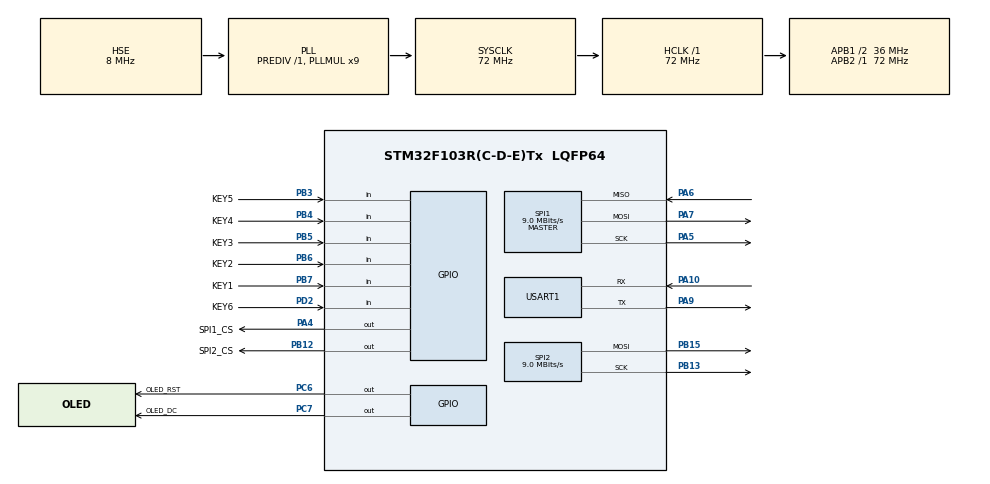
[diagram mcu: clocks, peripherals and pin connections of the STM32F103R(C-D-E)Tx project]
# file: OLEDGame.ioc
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Mcu.Family=STM32F1
Mcu.Name=STM32F103R(C-D-E)Tx
Mcu.Package=LQFP64
NVIC.PriorityGroup=NVIC_PRIORITYGROUP_4
NVIC.USART1_IRQn=true\:0\:0\:false\:false\:true\:true\:true
PA10.Mode=Asynchronous
PA10.Signal=USART1_RX
PA13.Mode=Serial_Wire
PA13.Signal=SYS_JTMS-SWDIO
PA14.Mode=Serial_Wire
PA14.Signal=SYS_JTCK-SWCLK
PA4.GPIO_Label=SPI1_CS
PA4.GPIO_Speed=GPIO_SPEED_FREQ_MEDIUM
PA4.PinState=GPIO_PIN_SET
PA4.Signal=GPIO_Output
PA5.Mode=Full_Duplex_Master
PA5.Signal=SPI1_SCK
PA6.Mode=Full_Duplex_Master
PA6.Signal=SPI1_MISO
PA7.Mode=Full_Duplex_Master
PA7.Signal=SPI1_MOSI
PA9.Mode=Asynchronous
PA9.Signal=USART1_TX
PB12.GPIO_Label=SPI2_CS
PB12.GPIO_Speed=GPIO_SPEED_FREQ_MEDIUM
PB12.PinState=GPIO_PIN_SET
PB12.Signal=GPIO_Output
PB13.Mode=TX_Only_Simplex_Unidirect_Master
PB13.Signal=SPI2_SCK
PB15.Mode=TX_Only_Simplex_Unidirect_Master
PB15.Signal=SPI2_MOSI
PB3.GPIO_Label=KEY5
PB3.GPIO_PuPd=GPIO_PULLUP
PB3.Signal=GPIO_Input
PB4.GPIO_Label=KEY4
PB4.GPIO_PuPd=GPIO_PULLUP
PB4.Signal=GPIO_Input
PB5.GPIO_Label=KEY3
PB5.GPIO_PuPd=GPIO_PULLUP
PB5.Signal=GPIO_Input
PB6.GPIO_Label=KEY2
PB6.GPIO_PuPd=GPIO_PULLUP
PB6.Signal=GPIO_Input
PB7.GPIO_Label=KEY1
PB7.GPIO_PuPd=GPIO_PULLUP
PB7.Signal=GPIO_Input
PC6.GPIO_Label=OLED_RST
PC6.GPIO_Speed=GPIO_SPEED_FREQ_MEDIUM
PC6.PinState=GPIO_PIN_SET
PC6.Signal=GPIO_Output
PC7.GPIO_Label=OLED_DC
PC7.GPIO_Speed=GPIO_SPEED_FREQ_MEDIUM
PC7.PinState=GPIO_PIN_SET
PC7.Signal=GPIO_Output
PD0-OSC_IN.Mode=HSE-External-Oscillator
PD0-OSC_IN.Signal=RCC_OSC_IN
PD1-OSC_OUT.Mode=HSE-External-Oscillator
PD1-OSC_OUT.Signal=RCC_OSC_OUT
PD2.GPIO_Label=KEY6
PD2.GPIO_PuPd=GPIO_PULLUP
PD2.Signal=GPIO_Input
ProjectManager.HeapSize=0x200
ProjectManager.StackSize=0x400
ProjectManager.TargetToolchain=MDK-ARM V5
RCC.AHBFreq_Value=72000000
RCC.APB1CLKDivider=RCC_HCLK_DIV2
RCC.APB1Freq_Value=36000000
RCC.APB1TimFreq_Value=72000000
RCC.APB2Freq_Value=72000000
RCC.APB2TimFreq_Value=72000000
RCC.EnbaleCSS=true
RCC.HCLKFreq_Value=72000000
RCC.PLLMUL=RCC_PLL_MUL9
RCC.PLLSourceVirtual=RCC_PLLSOURCE_HSE
RCC.SYSCLKFreq_VALUE=72000000
RCC.SYSCLKSource=RCC_SYSCLKSOURCE_PLLCLK
RCC.USBFreq_Value=72000000
SPI1.BaudRatePrescaler=SPI_BAUDRATEPRESCALER_8
SPI1.CalculateBaudRate=9.0 MBits/s
SPI1.Direction=SPI_DIRECTION_2LINES
SPI1.Mode=SPI_MODE_MASTER
SPI1.VirtualType=VM_MASTER
SPI2.BaudRatePrescaler=SPI_BAUDRATEPRESCALER_4
SPI2.CalculateBaudRate=9.0 MBits/s
SPI2.Direction=SPI_DIRECTION_2LINES
SPI2.Mode=SPI_MODE_MASTER
SPI2.VirtualType=VM_MASTER
USART1.VirtualMode=VM_ASYNC
board=custom

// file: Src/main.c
/* USER CODE BEGIN Header */
/**
  ******************************************************************************
  * @file           : main.c
  * @brief          : Main program body
  ******************************************************************************
  * @attention
  *
  * <h2><center>&copy; Copyright (c) 2020 STMicroelectronics.
  * All rights reserved.</center></h2>
  *
  * This software component is licensed by ST under BSD 3-Clause license,
  * the "License"; You may not use this file except in compliance with the
  * License. You may obtain a copy of the License at:
  *                        opensource.org/licenses/BSD-3-Clause
  *
  ******************************************************************************
  */
/* USER CODE END Header */

#include "main.h"
#include "spi.h"
#include "usart.h"
#include "gpio.h"
/* USER CODE BEGIN Includes */
#include "hopper.h"
/* USER CODE END Includes */

void SystemClock_Config(void);

int main(void)
{

  /* MCU Configuration--------------------------------------------------------*/

  /* Reset of all peripherals, Initializes the Flash interface and the Systick. */
  HAL_Init();

  /* Configure the system clock */
  SystemClock_Config();

  /* Initialize all configured peripherals */
  MX_GPIO_Init();
  MX_SPI1_Init();
  MX_SPI2_Init();
  MX_USART1_UART_Init();
  /* USER CODE BEGIN 2 */

	Init_OLED();

  /* USER CODE END 2 */

  /* Infinite loop */
  while (1)
  {
	 /* USER CODE BEGIN 3 */
	Hopper();
  }
  /* USER CODE END 3 */
}

void SystemClock_Config(void)
{
  RCC_OscInitTypeDef RCC_OscInitStruct = {0};
  RCC_ClkInitTypeDef RCC_ClkInitStruct = {0};

  /** Initializes the CPU, AHB and APB busses clocks
  */
  RCC_OscInitStruct.OscillatorType = RCC_OSCILLATORTYPE_HSE;
  RCC_OscInitStruct.HSEState = RCC_HSE_ON;
  RCC_OscInitStruct.HSEPredivValue = RCC_HSE_PREDIV_DIV1;
  RCC_OscInitStruct.HSIState = RCC_HSI_ON;
  RCC_OscInitStruct.PLL.PLLState = RCC_PLL_ON;
  RCC_OscInitStruct.PLL.PLLSource = RCC_PLLSOURCE_HSE;
  RCC_OscInitStruct.PLL.PLLMUL = RCC_PLL_MUL9;
  if (HAL_RCC_OscConfig(&RCC_OscInitStruct) != HAL_OK)
  {
    Error_Handler();
  }
  /** Initializes the CPU, AHB and APB busses clocks
  */
  RCC_ClkInitStruct.ClockType = RCC_CLOCKTYPE_HCLK|RCC_CLOCKTYPE_SYSCLK
                              |RCC_CLOCKTYPE_PCLK1|RCC_CLOCKTYPE_PCLK2;
  RCC_ClkInitStruct.SYSCLKSource = RCC_SYSCLKSOURCE_PLLCLK;
  RCC_ClkInitStruct.AHBCLKDivider = RCC_SYSCLK_DIV1;
  RCC_ClkInitStruct.APB1CLKDivider = RCC_HCLK_DIV2;
  RCC_ClkInitStruct.APB2CLKDivider = RCC_HCLK_DIV1;

  if (HAL_RCC_ClockConfig(&RCC_ClkInitStruct, FLASH_LATENCY_2) != HAL_OK)
  {
    Error_Handler();
  }
  /** Enables the Clock Security System
  */
  HAL_RCC_EnableCSS();
}

void Error_Handler(void)
{
}

/************************ (C) COPYRIGHT STMicroelectronics *****END OF FILE****/
